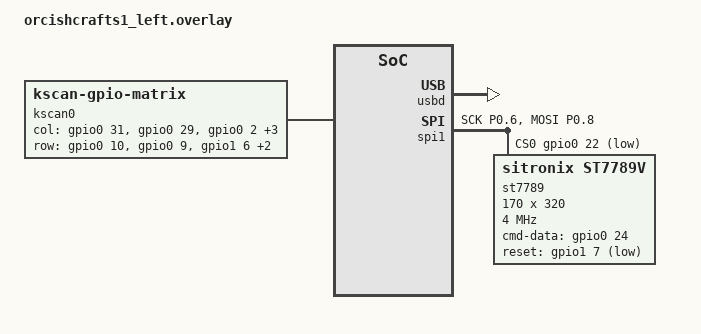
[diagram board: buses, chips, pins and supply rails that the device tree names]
#include "orcishcrafts1.dtsi"
#include <dt-bindings/pinctrl/nrf-pinctrl.h>

/ {
    chosen {
        zmk,kscan = &kscan0;
        zephyr,display = &st7789;
    };

    kscan0: kscan0 {
        compatible = "zmk,kscan-gpio-matrix";
        diode-direction = "col2row";
        wakeup-source;

        col-gpios
            = <&gpio0 31 GPIO_ACTIVE_HIGH> 
            , <&gpio0 29 GPIO_ACTIVE_HIGH> 
            , <&gpio0  2 GPIO_ACTIVE_HIGH> 
            , <&gpio1 15 GPIO_ACTIVE_HIGH> 
            , <&gpio1 13 GPIO_ACTIVE_HIGH> 
            , <&gpio1 11 GPIO_ACTIVE_HIGH> 
            ;

        row-gpios
            = <&gpio0 10 (GPIO_ACTIVE_HIGH | GPIO_PULL_DOWN)> 
            , <&gpio0  9 (GPIO_ACTIVE_HIGH | GPIO_PULL_DOWN)> 
            , <&gpio1  6 (GPIO_ACTIVE_HIGH | GPIO_PULL_DOWN)> 
            , <&gpio1  4 (GPIO_ACTIVE_HIGH | GPIO_PULL_DOWN)> 
            , <&gpio1  0 (GPIO_ACTIVE_HIGH | GPIO_PULL_DOWN)> 
            ;
    };
};

&usbd {
    status = "okay";
};

/* 
   THE PINTRL CLONE MAP:
   Maps your physical SCK track to Pin 0.06 and MOSI data track to Pin 0.08
   to match the literal layout of the SuperMini clone board footprint.
*/
&pinctrl {
    spi1_default: spi1_default {
        group1 {
            psels = <NRF_PSEL(SPI_SCK, 0, 6)>,  /* Raw literal mapping for SCK on Pin 0.06 */
                    <NRF_PSEL(SPI_MOSI, 0, 8)>; /* Raw literal mapping for MOSI on Pin 0.08 */
        };
    };
    spi1_sleep: spi1_sleep {
        group1 {
            psels = <NRF_PSEL(SPI_SCK, 0, 6)>,
                    <NRF_PSEL(SPI_MOSI, 0, 8)>;
            low-power-enable;
        };
    };
};

&spi1 {
    status = "okay";
    pinctrl-0 = <&spi1_default>;
    pinctrl-1 = <&spi1_sleep>;
    pinctrl-names = "default", "sleep";
    
    /* Dedicated Control Line Targets */
    cs-gpios = <&gpio0 22 GPIO_ACTIVE_LOW>; /* Pro Micro Pin 14 Footprint */

    st7789: st7789@0 {
        compatible = "sitronix,st7789v";
        reg = <0>;
        spi-max-frequency = <4000000>; 
        
        /* Control Lines Shifted to Safe, Free Matrix Pins */
        cmd-data-gpios = <&gpio0 24 GPIO_ACTIVE_HIGH>; /* Pro Micro Pin 15 Footprint */
        reset-gpios    = <&gpio1  7 GPIO_ACTIVE_LOW>;  /* Pro Micro Pin 16 Footprint */
        
        width = <170>;
        height = <320>;
        x-offset = <35>; 
        y-offset = <0>;
        
        vcom = <0x1c>;
        gctrl = <0x35>;
        mdac = <0x00>; 
        lcm = <0x2c>;
        colmod = <0x55>; 
        gamma = <0x01>;
        porch-param = [0c 0c 00 33 33]; 
        cmd2en-param = [5a 69 02 01];
        pwctrl1-param = [a4 a1];
        pvgam-param = [d0 04 0d 11 13 2b 3f 54 4c 18 0d 0b 1f 23];
        nvgam-param = [d0 04 0c 11 13 2c 3f 44 51 2f 1f 1f 20 23];
        ram-param = [2c 2e];
        rgb-param = [00 05 00];
    };
};
